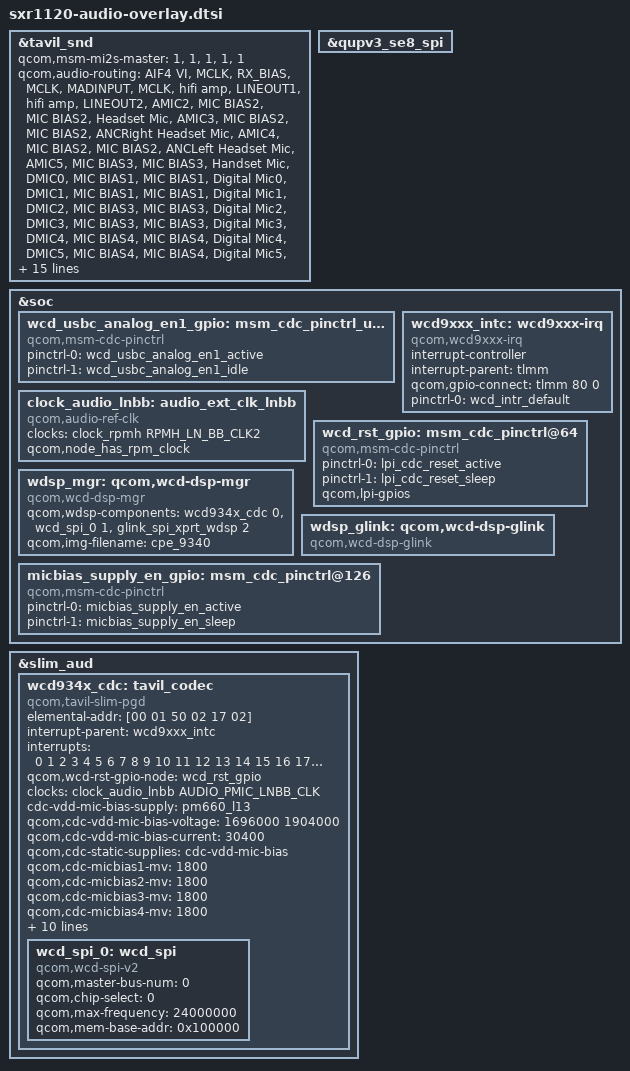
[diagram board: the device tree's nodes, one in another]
/*
 * Copyright (c) 2018, The Linux Foundation. All rights reserved.
 *
 * This program is free software; you can redistribute it and/or modify
 * it under the terms of the GNU General Public License version 2 and
 * only version 2 as published by the Free Software Foundation.
 *
 * This program is distributed in the hope that it will be useful,
 * but WITHOUT ANY WARRANTY; without even the implied warranty of
 * MERCHANTABILITY or FITNESS FOR A PARTICULAR PURPOSE.  See the
 * GNU General Public License for more details.
 */
#include "sdm670-wcd.dtsi"
#include "sdm670-wsa881x.dtsi"
#include "sdm670-lpi.dtsi"
#include <dt-bindings/clock/qcom,audio-ext-clk.h>

&tavil_snd {
	qcom,msm-mi2s-master = <1>, <1>, <1>, <1>, <1>;
	qcom,audio-routing =
		"AIF4 VI", "MCLK",
		"RX_BIAS", "MCLK",
		"MADINPUT", "MCLK",
		"hifi amp", "LINEOUT1",
		"hifi amp", "LINEOUT2",
		"AMIC2", "MIC BIAS2",
		"MIC BIAS2", "Headset Mic",
		"AMIC3", "MIC BIAS2",
		"MIC BIAS2", "ANCRight Headset Mic",
		"AMIC4", "MIC BIAS2",
		"MIC BIAS2", "ANCLeft Headset Mic",
		"AMIC5", "MIC BIAS3",
		"MIC BIAS3", "Handset Mic",
		"DMIC0", "MIC BIAS1",
		"MIC BIAS1", "Digital Mic0",
		"DMIC1", "MIC BIAS1",
		"MIC BIAS1", "Digital Mic1",
		"DMIC2", "MIC BIAS3",
		"MIC BIAS3", "Digital Mic2",
		"DMIC3", "MIC BIAS3",
		"MIC BIAS3", "Digital Mic3",
		"DMIC4", "MIC BIAS4",
		"MIC BIAS4", "Digital Mic4",
		"DMIC5", "MIC BIAS4",
		"MIC BIAS4", "Digital Mic5",
		"SpkrLeft IN", "SPK1 OUT",
		"SpkrRight IN", "SPK2 OUT";

	qcom,msm-mbhc-hphl-swh = <1>;
	qcom,msm-mbhc-gnd-swh = <1>;
	qcom,hph-en0-gpio = <&tavil_hph_en0>;
	qcom,hph-en1-gpio = <&tavil_hph_en1>;
	qcom,msm-mclk-freq = <9600000>;
	asoc-codec = <&stub_codec>, <&ext_disp_audio_codec>;
	asoc-codec-names = "msm-stub-codec.1", "msm-ext-disp-audio-codec-rx";
	qcom,wsa-max-devs = <2>;
	qcom,wsa-devs = <&wsa881x_0211>, <&wsa881x_0212>,
		<&wsa881x_0213>, <&wsa881x_0214>;
	qcom,wsa-aux-dev-prefix = "SpkrLeft", "SpkrRight",
		"SpkrLeft", "SpkrRight";
};

&qupv3_se8_spi{
	status = "okay";
};

&soc {
	wcd_usbc_analog_en1_gpio: msm_cdc_pinctrl_usbc_audio_en1 {
		compatible = "qcom,msm-cdc-pinctrl";
		pinctrl-names = "aud_active", "aud_sleep";
		pinctrl-0 = <&wcd_usbc_analog_en1_active>;
		pinctrl-1 = <&wcd_usbc_analog_en1_idle>;
	};

	wcd9xxx_intc: wcd9xxx-irq {
		status = "okay";
		compatible = "qcom,wcd9xxx-irq";
		interrupt-controller;
		#interrupt-cells = <1>;
		interrupt-parent = <&tlmm>;
		qcom,gpio-connect = <&tlmm 80 0>;
		pinctrl-names = "default";
		pinctrl-0 = <&wcd_intr_default>;
	};

	clock_audio_lnbb: audio_ext_clk_lnbb {
		status = "okay";
		compatible = "qcom,audio-ref-clk";
		clock-names = "osr_clk";
		clocks = <&clock_rpmh RPMH_LN_BB_CLK2>;
		qcom,node_has_rpm_clock;
		#clock-cells = <1>;
	};

	wcd_rst_gpio: msm_cdc_pinctrl@64 {
		status = "okay";
		compatible = "qcom,msm-cdc-pinctrl";
		pinctrl-names = "aud_active", "aud_sleep";
		pinctrl-0 = <&lpi_cdc_reset_active>;
		pinctrl-1 = <&lpi_cdc_reset_sleep>;
		qcom,lpi-gpios;
	};

	wdsp_mgr: qcom,wcd-dsp-mgr {
		status = "okay";
		compatible = "qcom,wcd-dsp-mgr";
		qcom,wdsp-components = <&wcd934x_cdc 0>,
				       <&wcd_spi_0 1>,
				       <&glink_spi_xprt_wdsp 2>;
					qcom,img-filename = "cpe_9340";
	};

	wdsp_glink: qcom,wcd-dsp-glink {
		status = "okay";
		compatible = "qcom,wcd-dsp-glink";
	};

	micbias_supply_en_gpio: msm_cdc_pinctrl@126 {
		status = "okay";
		compatible = "qcom,msm-cdc-pinctrl";
		pinctrl-names = "aud_active", "aud_sleep";
		pinctrl-0 = <&micbias_supply_en_active>;
		pinctrl-1 = <&micbias_supply_en_sleep>;
	};

};

&slim_aud {
	wcd934x_cdc: tavil_codec {
		status = "okay";
		compatible = "qcom,tavil-slim-pgd";
		elemental-addr = [00 01 50 02 17 02];

		interrupt-parent = <&wcd9xxx_intc>;
		interrupts = <0 1 2 3 4 5 6 7 8 9 10 11 12 13 14 15 16
			      17 18 19 20 21 22 23 24 25 26 27 28 29
			      30 31>;

		qcom,wcd-rst-gpio-node = <&wcd_rst_gpio>;

		clock-names = "wcd_clk";
		clocks = <&clock_audio_lnbb AUDIO_PMIC_LNBB_CLK>;

		cdc-vdd-mic-bias-supply = <&pm660_l13>;
		qcom,cdc-vdd-mic-bias-voltage = <1696000 1904000>;
		qcom,cdc-vdd-mic-bias-current = <30400>;

		qcom,cdc-static-supplies = "cdc-vdd-mic-bias";

		qcom,cdc-micbias1-mv = <1800>;
		qcom,cdc-micbias2-mv = <1800>;
		qcom,cdc-micbias3-mv = <1800>;
		qcom,cdc-micbias4-mv = <1800>;

		qcom,cdc-mclk-clk-rate = <9600000>;
		qcom,cdc-slim-ifd = "tavil-slim-ifd";
		qcom,cdc-slim-ifd-elemental-addr = [00 00 50 02 17 02];
		qcom,cdc-dmic-sample-rate = <4800000>;
		qcom,cdc-mad-dmic-rate = <600000>;

		qcom,wdsp-cmpnt-dev-name = "tavil_codec";

		qcom,has-micbias-supply-en-gpio;
		qcom,micbias-supply-en-gpio-node = <&micbias_supply_en_gpio>;

		wcd_spi_0: wcd_spi {
			compatible = "qcom,wcd-spi-v2";
			qcom,master-bus-num = <0>;
			qcom,chip-select = <0>;
			qcom,max-frequency = <24000000>;
			qcom,mem-base-addr = <0x100000>;
		};
	};
};
